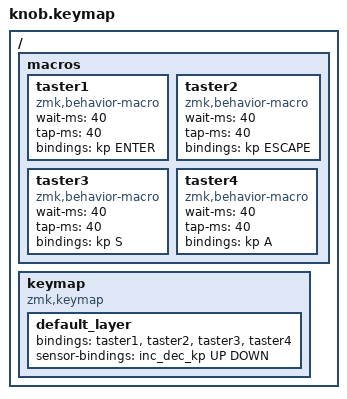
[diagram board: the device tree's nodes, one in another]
#include <behaviors.dtsi>
#include <dt-bindings/zmk/keys.h>
#include <dt-bindings/zmk/bt.h>
#include <dt-bindings/zmk/outputs.h>

/ {
    macros {
        taster1: taster1 {
            compatible = "zmk,behavior-macro";
            #binding-cells = <0>;
            wait-ms = <40>;
            tap-ms = <40>;
            bindings = 
                <&kp ENTER>;
        };
        taster2: taster2 {
            compatible = "zmk,behavior-macro";
            #binding-cells = <0>;
            wait-ms = <40>;
            tap-ms = <40>;
            bindings = 
                <&kp ESCAPE>;
        };
        taster3: taster3 {
            compatible = "zmk,behavior-macro";
            #binding-cells = <0>;
            wait-ms = <40>;
            tap-ms = <40>;
            bindings = 
                <&kp S>;
        };
        taster4: taster4 {
            compatible = "zmk,behavior-macro";
            #binding-cells = <0>;
            wait-ms = <40>;
            tap-ms = <40>;
            bindings = 
                <&kp A>;
        };
    };
    keymap {
        compatible = "zmk,keymap";

        default_layer {
            bindings = <
                &taster1  &taster2  &taster3  &taster4
            >;
            sensor-bindings = <&inc_dec_kp UP DOWN>;
        };
    };
};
